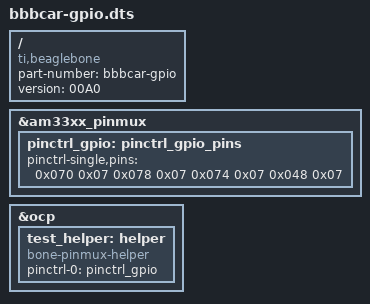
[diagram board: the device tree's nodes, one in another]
/dts-v1/;
/plugin/;

/ {
    compatible = "ti,beaglebone","ti,beaglebone-black";

    part-number = "bbbcar-gpio";
    version = "00A0";

    fragment@0 {
        target = <&am33xx_pinmux>;
        __overlay__ {
            pinctrl_gpio: pinctrl_gpio_pins {
                pinctrl-single,pins = <
					0x070 0x07  /* P9_11 */
                    0x078 0x07  /* P9_12 */
                    0x074 0x07  /* P9_13 */
                    0x048 0x07  /* P9_14 */
                >;
            };
        };
    };

    fragment@1 {
        target = <&ocp>;
        __overlay__ {
            test_helper: helper {
                compatible = "bone-pinmux-helper";
                pinctrl-names = "default";
                pinctrl-0 = <&pinctrl_gpio>;
                status = "okay";
            };
        };
    };
};
